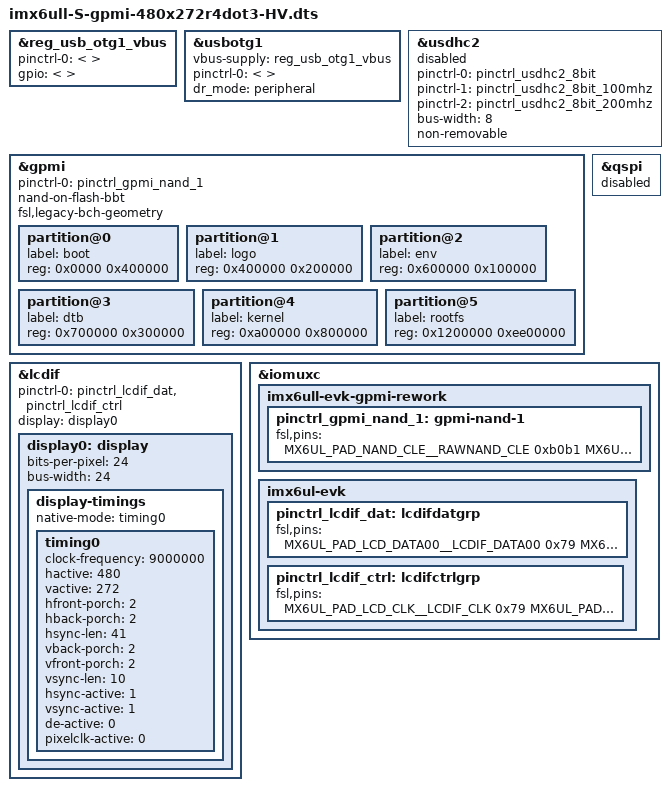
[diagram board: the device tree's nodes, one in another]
/*
 * Copyright (C) 2016 Freescale Semiconductor, Inc.
 *
 * This program is free software; you can redistribute it and/or modify
 * it under the terms of the GNU General Public License version 2 as
 * published by the Free Software Foundation.
 */

#include "imx6ull-14x14-evk.dts"

&reg_usb_otg1_vbus {
        pinctrl-0 = < >;
        gpio = < >;
};
&usbotg1 {
        vbus-supply = <&reg_usb_otg1_vbus>;
        pinctrl-names = "default";
        pinctrl-0 = < >;
        dr_mode = "peripheral";
        status = "okay";
};
&usdhc2 {
    pinctrl-names = "default", "state_100mhz", "state_200mhz";
    pinctrl-0 = <&pinctrl_usdhc2_8bit>;
    pinctrl-1 = <&pinctrl_usdhc2_8bit_100mhz>;
    pinctrl-2 = <&pinctrl_usdhc2_8bit_200mhz>;
    bus-width = <8>;
    non-removable;
    status = "disabled";
};

&gpmi {
    pinctrl-names = "default";
    pinctrl-0 = <&pinctrl_gpmi_nand_1>;
    nand-on-flash-bbt;
    fsl,legacy-bch-geometry;
    status = "okay";
    partition@0{
        label = "boot";
        reg = <0x0000 0x400000>; /*4M*/
    };
    partition@1{
        label = "logo";
        reg = <0x400000 0x200000>; /*2M*/
    };
    partition@2{
        label = "env";
        reg = <0x600000 0x100000>; /*1M*/
    };
    partition@3{
        label = "dtb";
        reg = <0x700000 0x300000>; /*3M*/
    };
    partition@4{
        label = "kernel";
        reg = <0xa00000 0x800000>; /*8M*/
    };
    partition@5{
        label = "rootfs";
        reg = <0x1200000 0xee00000>;
     };
};

&lcdif {
	pinctrl-names = "default";
        pinctrl-0 = <&pinctrl_lcdif_dat
                     &pinctrl_lcdif_ctrl>;
        display = <&display0>;
        status = "okay";

	display0: display {
		bits-per-pixel = <24>;
		bus-width = <24>;

		display-timings {
			native-mode = <&timing0>;
			timing0: timing0 {
			clock-frequency = <9000000>;
			hactive = <480>;
			vactive = <272>;
			hfront-porch = <2>;
			hback-porch = <2>;
			hsync-len = <41>;
			vback-porch = <2>;
			vfront-porch = <2>;
			vsync-len = <10>;

			hsync-active = <1>;
			vsync-active = <1>;
			de-active = <0>;
			pixelclk-active = <0>;
			};
		};
	};
};

&qspi {
    status = "disabled";
};

&iomuxc {
    imx6ull-evk-gpmi-rework {
 pinctrl_gpmi_nand_1: gpmi-nand-1 {
            fsl,pins = <
                MX6UL_PAD_NAND_CLE__RAWNAND_CLE         0xb0b1
                MX6UL_PAD_NAND_ALE__RAWNAND_ALE         0xb0b1
                MX6UL_PAD_NAND_WP_B__RAWNAND_WP_B       0xb0b1
                MX6UL_PAD_NAND_READY_B__RAWNAND_READY_B 0xb000
                MX6UL_PAD_NAND_CE0_B__RAWNAND_CE0_B     0xb0b1
                MX6UL_PAD_NAND_CE1_B__RAWNAND_CE1_B     0xb0b1
                MX6UL_PAD_NAND_RE_B__RAWNAND_RE_B       0xb0b1
                MX6UL_PAD_NAND_WE_B__RAWNAND_WE_B       0xb0b1
                MX6UL_PAD_NAND_DATA00__RAWNAND_DATA00   0xb0b1
                MX6UL_PAD_NAND_DATA01__RAWNAND_DATA01   0xb0b1
                MX6UL_PAD_NAND_DATA02__RAWNAND_DATA02   0xb0b1
                MX6UL_PAD_NAND_DATA03__RAWNAND_DATA03   0xb0b1
                MX6UL_PAD_NAND_DATA04__RAWNAND_DATA04   0xb0b1
                MX6UL_PAD_NAND_DATA05__RAWNAND_DATA05   0xb0b1
                MX6UL_PAD_NAND_DATA06__RAWNAND_DATA06   0xb0b1
                MX6UL_PAD_NAND_DATA07__RAWNAND_DATA07   0xb0b1
            >;
        };
    };

    imx6ul-evk {
		pinctrl_lcdif_dat: lcdifdatgrp {
			fsl,pins = <
				MX6UL_PAD_LCD_DATA00__LCDIF_DATA00  0x79
				MX6UL_PAD_LCD_DATA01__LCDIF_DATA01  0x79
				MX6UL_PAD_LCD_DATA02__LCDIF_DATA02  0x79
				MX6UL_PAD_LCD_DATA03__LCDIF_DATA03  0x79
				MX6UL_PAD_LCD_DATA04__LCDIF_DATA04  0x79
				MX6UL_PAD_LCD_DATA05__LCDIF_DATA05  0x79
				MX6UL_PAD_LCD_DATA06__LCDIF_DATA06  0x79
				MX6UL_PAD_LCD_DATA07__LCDIF_DATA07  0x79
				MX6UL_PAD_LCD_DATA08__LCDIF_DATA08  0x79
				MX6UL_PAD_LCD_DATA09__LCDIF_DATA09  0x79
				MX6UL_PAD_LCD_DATA10__LCDIF_DATA10  0x79
				MX6UL_PAD_LCD_DATA11__LCDIF_DATA11  0x79
				MX6UL_PAD_LCD_DATA12__LCDIF_DATA12  0x79
				MX6UL_PAD_LCD_DATA13__LCDIF_DATA13  0x79
				MX6UL_PAD_LCD_DATA14__LCDIF_DATA14  0x79
				MX6UL_PAD_LCD_DATA15__LCDIF_DATA15  0x79
				MX6UL_PAD_LCD_DATA16__LCDIF_DATA16  0x79
				MX6UL_PAD_LCD_DATA17__LCDIF_DATA17  0x79
				MX6UL_PAD_LCD_DATA18__LCDIF_DATA18  0x79
				MX6UL_PAD_LCD_DATA19__LCDIF_DATA19  0x79
				MX6UL_PAD_LCD_DATA20__LCDIF_DATA20  0x79
				MX6UL_PAD_LCD_DATA21__LCDIF_DATA21  0x79
				MX6UL_PAD_LCD_DATA22__LCDIF_DATA22  0x79
				MX6UL_PAD_LCD_DATA23__LCDIF_DATA23  0x79
			>;
		};

		pinctrl_lcdif_ctrl: lcdifctrlgrp {
			fsl,pins = <
				MX6UL_PAD_LCD_CLK__LCDIF_CLK	    0x79
				MX6UL_PAD_LCD_ENABLE__LCDIF_ENABLE  0x79
				MX6UL_PAD_LCD_HSYNC__LCDIF_HSYNC    0x79  
				MX6UL_PAD_LCD_VSYNC__LCDIF_VSYNC    0x79
				/* used for lcd reset */
	/*			MX6UL_PAD_SNVS_TAMPER9__GPIO5_IO09  0x79  */
			>;
		};	
	};	
};

                                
